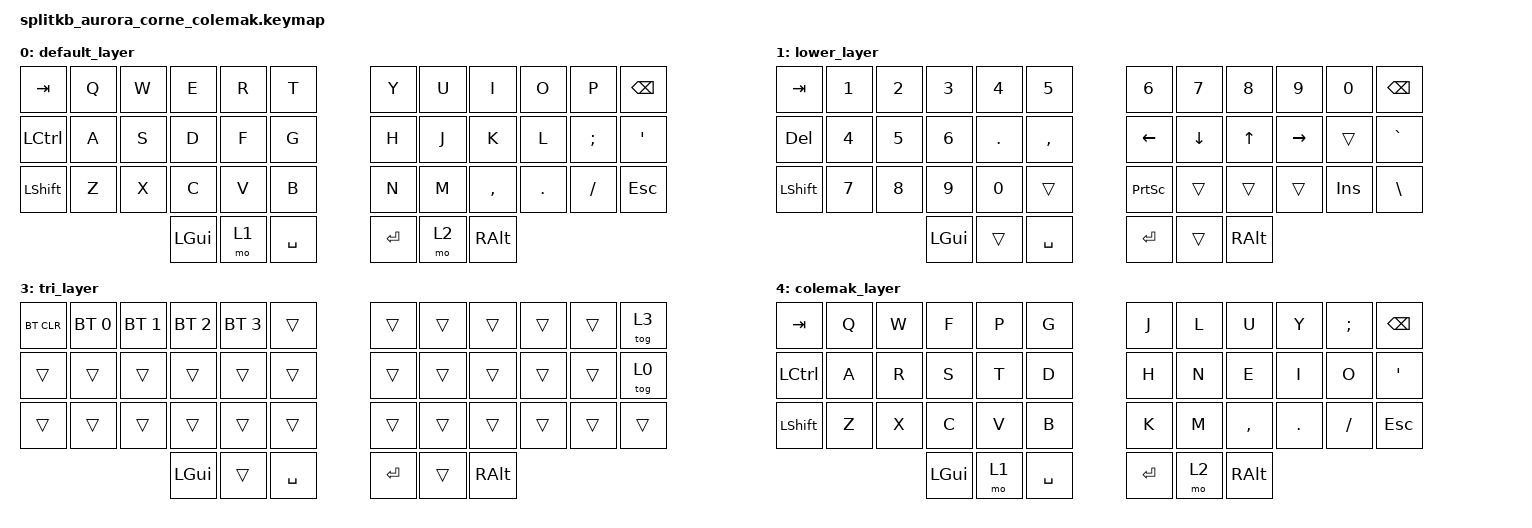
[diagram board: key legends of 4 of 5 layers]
/*
 * Copyright (c) 2020 The ZMK Contributors
 *
 * SPDX-License-Identifier: MIT
 *
 * Layout created by: Javi Oroz (github.com/javioroz/zmk-config)
 */
// ------ Libraries ------------------------------------------------------------------------
#include <behaviors.dtsi>
#include <dt-bindings/zmk/keys.h>
#include <dt-bindings/zmk/bt.h>

// ------ Layer definition -----------------------------------------------------------------
// #define DEFAULT 0
// #define NUMBER 1
// #define SYMBOL 2
// #define FUNCTION 3
// #define MEDIA 4
// #define MOUSE 5
// ------ main bracket ---------------------------------------------------------------------
/ {
    // -------------------------------------------------------------------------------------------------------------------------
    behaviors {
        ht: hold_tap {
            label = "hold_tap";
            compatible = "zmk,behavior-hold-tap";
            #binding-cells = <2>;
            flavor = "tap-preferred";
            tapping-term-ms = <220>;
            quick-tap-ms = <150>;
            global-quick-tap;
            bindings = <&kp>,<&kp>;
        };
    };
        
    conditional_layers {
        compatible = "zmk,conditional-layers";
        tri_layer {
            if-layers = <1 2>;
            then-layer = <3>;
        };
    };
    
    // -------------------------------------------------------------------------------------------------------------------------
    keymap {
        compatible = "zmk,keymap";

        default_layer {
            bindings = <
// ┌─────────┬─────────┬─────────┬─────────┬─────────┬─────────┐   ┌─────────┬─────────┬─────────┬─────────┬─────────┬─────────┐ 
// |   TAB   |    Q    |    W    |    E    |    R    |    T    |   |    Y    |    U    |    I    |    O    |    P    |   BKSP  |
    &kp TAB   &kp Q     &kp W     &kp E     &kp R     &kp T         &kp Y     &kp U     &kp I     &kp O     &kp P     &kp BSPC
// ├─────────┼─────────┼─────────┼─────────┼─────────┼─────────┤   ├─────────┼─────────┼─────────┼─────────┼─────────┼─────────┤ 
// |  CTRL   |    A    |    S    |    D    |    F    |    G    |   |    H    |    J    |    K    |    L    |    ;    |    '    |
   &kp LCTRL  &kp A     &kp S     &kp D     &kp F     &kp G         &kp H     &kp J     &kp K     &kp L     &kp SEMI  &kp SQT
// ├─────────┼─────────┼─────────┼─────────┼─────────┼─────────┤   ├─────────┼─────────┼─────────┼─────────┼─────────┼─────────┤ 
// |  SHFT   |    Z    |    X    |    C    |    V    |    B    |   |    N    |    M    |    ,    |    .    |    /    |   ESC   |
   &kp LSHFT  &kp Z     &kp X     &kp C     &kp V     &kp B         &kp N     &kp M     &kp COMMA  &kp DOT   &kp FSLH  &kp ESC
// └─────────┴─────────┴─────────┼─────────┼─────────┼─────────┤   ├─────────┼─────────┼─────────┼─────────┴─────────┴─────────┘ 
//                               |   GUI   |  LOWER  |  SPACE  |   |  ENTER  |  RAISE  |   ALT   |
                                  &kp LGUI  &mo 1     &kp SPACE     &kp RET   &mo 2     &kp RALT
//                               └─────────┴─────────┴─────────┘   └─────────┴─────────┴─────────┘
            >;
        };
        lower_layer {
            bindings = <
// ┌─────────┬─────────┬─────────┬─────────┬─────────┬─────────┐   ┌─────────┬─────────┬─────────┬─────────┬─────────┬─────────┐ 
// |   TAB   |    1    |    2    |    3    |    4    |    5    |   |    6    |    7    |    8    |    9    |    0    |   BKSP  |
    &kp TAB   &kp N1    &kp N2    &kp N3    &kp N4    &kp N5        &kp N6    &kp N7    &kp N8    &kp N9    &kp N0    &kp BSPC
// ├─────────┼─────────┼─────────┼─────────┼─────────┼─────────┤   ├─────────┼─────────┼─────────┼─────────┼─────────┼─────────┤ 
// |   DEL   |    4    |    5    |    6    |    .    |    ,    |   |   LFT   |   DWN   |    UP   |   RGT   |    Ñ    |    `    |
    &kp DEL   &kp N4    &kp N5    &kp N6    &kp DOT   &kp COMMA     &kp LEFT  &kp DOWN  &kp UP    &kp RIGHT  &trans   &kp GRAVE
// ├─────────┼─────────┼─────────┼─────────┼─────────┼─────────┤   ├─────────┼─────────┼─────────┼─────────┼─────────┼─────────┤ 
// |   SHFT  |    7    |    8    |    9    |    0    |    €    |   | PrnScrn |         |         |         | INSERT  |    \    |
    &kp LSHFT  &kp N7   &kp N8    &kp N9    &kp N0     &trans      &kp PSCRN  &trans     &trans   &trans     &kp INS  &kp BSLH
// └─────────┴─────────┴─────────┼─────────┼─────────┼─────────┤   ├─────────┼─────────┼─────────┼─────────┴─────────┴─────────┘ 
//                               |   GUI   |         |   SPC   |   |   ENT   |         |   ALT   |
                          	  &kp LGUI   &trans    &kp SPACE    &kp RET    &trans   &kp RALT
//                               └─────────┴─────────┴─────────┘   └─────────┴─────────┴─────────┘

            >;
        };

        raise_layer {
            bindings = <
// ┌─────────┬─────────┬─────────┬─────────┬─────────┬─────────┐   ┌─────────┬─────────┬─────────┬─────────┬─────────┬─────────┐ 
// |    TAB  |    !    |    @    |    #    |    $    |    %    |   |    ^    |    &    |    *    |    (    |    )    |   BKSP  |
    &kp TAB   &kp EXCL  &kp AT   &kp HASH   &kp DLLR  &kp PRCNT     &kp CARET &kp AMPS  &kp ASTRK &kp LPAR  &kp RPAR  &kp BSPC
// ├─────────┼─────────┼─────────┼─────────┼─────────┼─────────┤   ├─────────┼─────────┼─────────┼─────────┼─────────┼─────────┤ 
// |    DEL  |    F1   |   F2    |   F3    |   F4    |   F5    |   |   F6    |    -    |    =    |    [    |    ]    |    ~    |
    &kp DEL   &kp F1    &kp F2    &kp F3    &kp F4    &kp F5        &kp F6    &kp MINUS &kp EQUAL &kp LBKT  &kp RBKT  &kp TILDE
// ├─────────┼─────────┼─────────┼─────────┼─────────┼─────────┤   ├─────────┼─────────┼─────────┼─────────┼─────────┼─────────┤ 
// |   SHFT  |    F7   |   F8    |   F9    |   F10   |   F11   |   |   F12   |    _    |    +    |    {    |    }    |   "|"   |
    &kp LSHF T&kp F7    &kp F8    &kp F9    &kp F10    &kp F11      &kp F12   &kp UNDER &kp PLUS  &kp LBRC  &kp RBRC  &kp PIPE
// └─────────┴─────────┴─────────┼─────────┼─────────┼─────────┤   ├─────────┼─────────┼─────────┼─────────┴─────────┴─────────┘ 
//                               |   GUI   |         |  SPACE  |   |  ENTER  |         |   ALT   |
//                               └─────────┴─────────┴─────────┘   └─────────┴─────────┴─────────┘

                    	     &kp LGUI &trans   &kp SPACE   &kp RET   &trans    &kp RALT
            >;
        };
        tri_layer {
            bindings = <
// ┌─────────┬─────────┬─────────┬─────────┬─────────┬─────────┐   ┌─────────┬─────────┬─────────┬─────────┬─────────┬─────────┐ 
// |  BTCLR  |  BT1    |  BT2    |  BT3    |  BT4    |         |   |         |         |         |         |         |TO COLEMAK|
&bt BT_CLR &bt BT_SEL 0 &bt BT_SEL 1 &bt BT_SEL 2 &bt BT_SEL 3 &trans &trans   &trans    &trans    &trans    &trans   &tog 3
// ├─────────┼─────────┼─────────┼─────────┼─────────┼─────────┤   ├─────────┼─────────┼─────────┼─────────┼─────────┼─────────┤ 
// |         |         |         |         |         |         |   |         |         |         |         |         |TO DEFAULT|
     &trans     &trans   &trans    &trans    &trans    &trans      &trans   &trans    &trans    &trans    &trans     &tog 0
// ├─────────┼─────────┼─────────┼─────────┼─────────┼─────────┤   ├─────────┼─────────┼─────────┼─────────┼─────────┼─────────┤ 
// |         |         |         |         |         |         |   |         |         |         |         |         |         |
     &trans    &trans    &trans    &trans    &trans     &trans         &trans    &trans   &trans    &trans    &trans    &trans 
// └─────────┴─────────┴─────────┼─────────┼─────────┼─────────┤   ├─────────┼─────────┼─────────┼─────────┴─────────┴─────────┘ 
//                               |   GUI   |         |   SPC   |   |   ENT   |         |   ALT   |
                          	   &kp LGUI     &trans       &kp SPACE      &kp RET  &trans   &kp RALT
//                               └─────────┴─────────┴─────────┘   └─────────┴─────────┴─────────┘

            >;
        };
        colemak_layer {
             bindings = <
// ┌─────────┬─────────┬─────────┬─────────┬─────────┬─────────┐   ┌─────────┬─────────┬─────────┬─────────┬─────────┬─────────┐ 
// |   TAB   |    Q    |    W    |    F    |    P    |    G    |   |    J    |    L    |    U    |    Y    |    ;    |   BKSP  |
    &kp TAB   &kp Q     &kp W     &kp F     &kp P     &kp G         &kp J     &kp L     &kp U     &kp Y     &kp SEMI   &kp BSPC
// ├─────────┼─────────┼─────────┼─────────┼─────────┼─────────┤   ├─────────┼─────────┼─────────┼─────────┼─────────┼─────────┤ 
// |  CTRL   |    A    |    R    |    S    |    T    |    D    |   |    H    |    N    |    E    |    I    |    O    |    '    |
   &kp LCTRL  &kp A     &kp R     &kp S     &kp T     &kp D         &kp H     &kp N     &kp E     &kp I     &kp O      &kp SQT
// ├─────────┼─────────┼─────────┼─────────┼─────────┼─────────┤   ├─────────┼─────────┼─────────┼─────────┼─────────┼─────────┤ 
// |  SHFT   |    Z    |    X    |    C    |    V    |    B    |   |    K    |    M    |    ,    |    .    |    /    |   ESC   |
   &kp LSHFT  &kp Z     &kp X     &kp C     &kp V     &kp B         &kp K     &kp M     &kp COMMA  &kp DOT   &kp FSLH  &kp ESC
// └─────────┴─────────┴─────────┼─────────┼─────────┼─────────┤   ├─────────┼─────────┼─────────┼─────────┴─────────┴─────────┘ 
//                               |   GUI   |  LOWER  |  SPACE  |   |  ENTER  |  RAISE  |   ALT   |
                                  &kp LGUI  &mo 1     &kp SPACE     &kp RET   &mo 2     &kp RALT
//                               └─────────┴─────────┴─────────┘   └─────────┴─────────┴─────────┘
            >;
        };
        };
        minimak_layer {
             bindings = <
// ┌─────────┬─────────┬─────────┬─────────┬─────────┬─────────┐   ┌─────────┬─────────┬─────────┬─────────┬─────────┬─────────┐ 
// |   TAB   |    Q    |    W    |    T    |    F    |    K    |   |    Y    |    U    |    I    |    L    |    ;    |   BKSP  |
    &kp TAB   &kp Q     &kp W     &kp T     &kp F     &kp K         &kp Y     &kp U     &kp I     &kp L     &kp SEMI   &kp BSPC
// ├─────────┼─────────┼─────────┼─────────┼─────────┼─────────┤   ├─────────┼─────────┼─────────┼─────────┼─────────┼─────────┤ 
// |  CTRL   |    A    |    S    |    D    |    R    |    G    |   |    H    |    N    |    E    |    O    |    P    |    '    |
   &kp LCTRL  &kp A     &kp R     &kp D     &kp R     &kp G         &kp H     &kp N     &kp I     &kp O     &kp N      &kp SQT
// ├─────────┼─────────┼─────────┼─────────┼─────────┼─────────┤   ├─────────┼─────────┼─────────┼─────────┼─────────┼─────────┤ 
// |  SHFT   |    Z    |    X    |    C    |    V    |    B    |   |    J    |    M    |    ,    |    .    |    /    |   ESC   |
   &kp LSHFT  &kp Z     &kp X     &kp C     &kp V     &kp B         &kp J     &kp M     &kp COMMA  &kp DOT   &kp FSLH  &kp ESC
// └─────────┴─────────┴─────────┼─────────┼─────────┼─────────┤   ├─────────┼─────────┼─────────┼─────────┴─────────┴─────────┘ 
//                               |   GUI   |  LOWER  |  SPACE  |   |  ENTER  |  RAISE  |   ALT   |
                                  &kp LGUI  &mo 1     &kp SPACE     &kp RET   &mo 2     &kp RALT
//                               └─────────┴─────────┴─────────┘   └─────────┴─────────┴─────────┘
            >;
        };
    }; // ------ keymap bracket ends
}; // ------- main bracket ends

// ------------------- HELP NOTES -----------------------------------------------------------
//
// &kp: key pressed (used for normal keys)
// &bt: bluetooth function
// &mo: momentary layout change (only while key is holded)
// &ht: hold-tap will output the 1st key if it's held for a while, and output the 2nd when it's tapped quickly
// &tog: switches to layer number and we keep staying on that new label
// &
//

